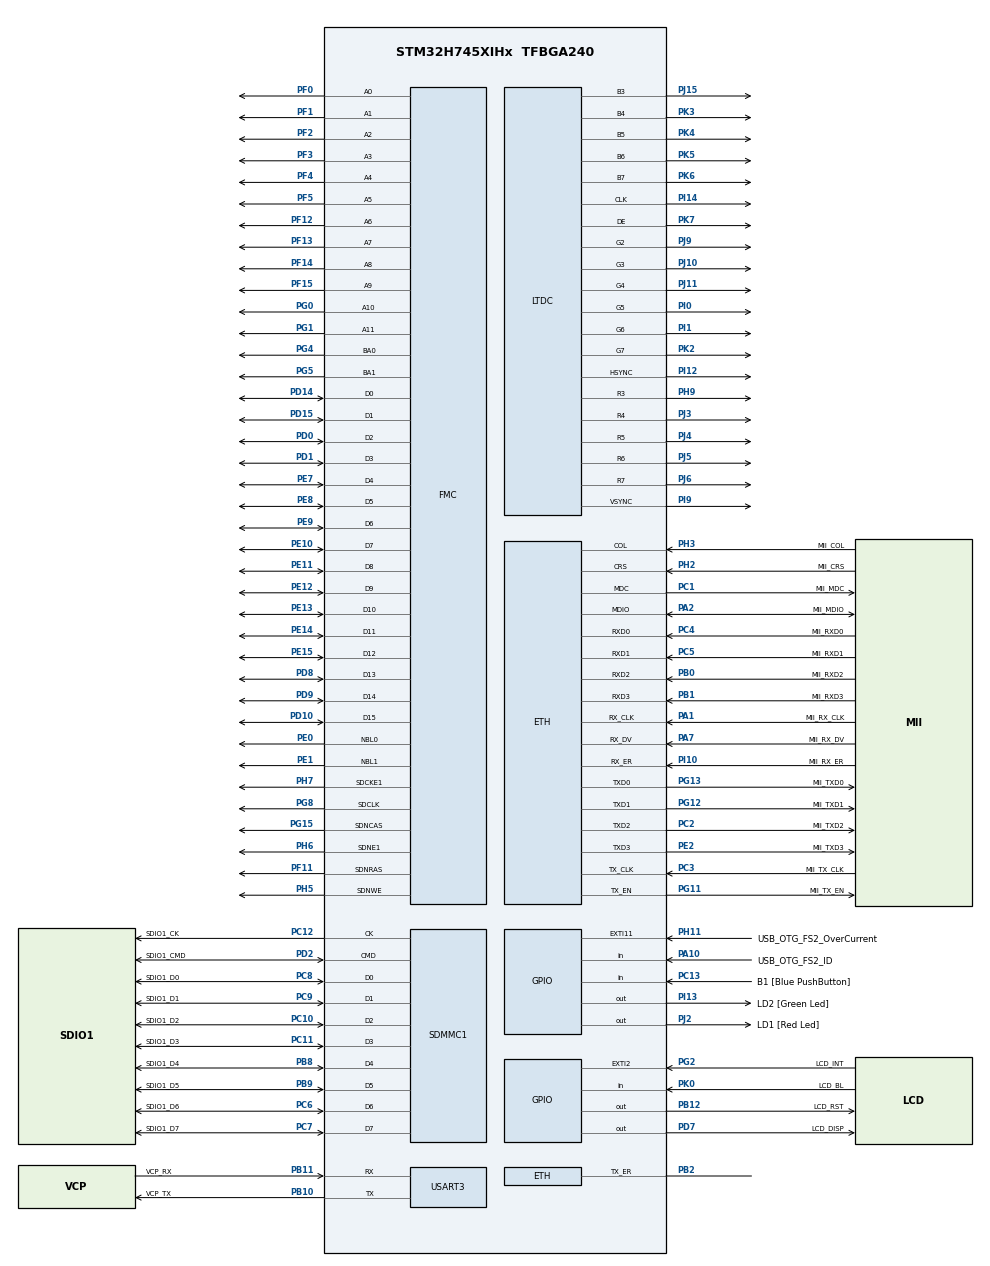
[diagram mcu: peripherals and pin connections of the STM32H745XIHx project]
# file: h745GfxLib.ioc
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CortexM4.IPs=FATFS_M4\:I,FREERTOS_M4\:I,IWDG2\:I,RCC,USB_DEVICE_M4\:I,USB_HOST_M4\:I,WWDG2\:I,DMA,BDMA,MDMA,NVIC2\:I,SAI4\:I,DEBUG,PDM2PCM_M4\:I,PWR,RESMGR_UTILITY,SYS_M4\:I,CORTEX_M4\:I,GPIO,OPENAMP_M4\:I,VREFBUF
CortexM4.Pins=PJ2
CortexM7.IPs=FATFS_M7\:I,FREERTOS_M7\:I,IWDG1\:I,RCC\:I,USB_DEVICE_M7\:I,USB_HOST_M7\:I,WWDG1\:I,DMA\:I,BDMA\:I,MDMA\:I,NVIC1\:I,CORTEX_M7\:I,DEBUG\:I,PDM2PCM_M7\:I,PWR\:I,RESMGR_UTILITY\:I,SYS\:I,GPIO\:I,OPENAMP_M7\:I,VREFBUF\:I,MEMORYMAP\:I,LTDC\:I,USART3\:I,FMC\:I,RNG\:I,SDMMC1\:I,ETH\:I,LWIP\:I,TIM2\:I
CortexM7.Pins=PD7,PA10,PC13,PI13,PG2,PK0,PH11,PB12
ETH.MediaInterface=HAL_ETH_MII_MODE
FATFS_M7._VOLUMES=2
FMC.CASLatency2=FMC_SDRAM_CAS_LATENCY_3
FMC.ExitSelfRefreshDelay2=6
FMC.LoadToActiveDelay2=2
FMC.RCDDelay2=2
FMC.RPDelay1=2
FMC.RPDelay2=2
FMC.ReadBurst1=FMC_SDRAM_RBURST_ENABLE
FMC.ReadBurst2=FMC_SDRAM_RBURST_ENABLE
FMC.ReadPipeDelay2=FMC_SDRAM_RPIPE_DELAY_0
FMC.RowCycleDelay1=6
FMC.RowCycleDelay2=6
FMC.SDClockPeriod1=FMC_SDRAM_CLOCK_PERIOD_2
FMC.SDClockPeriod2=FMC_SDRAM_CLOCK_PERIOD_2
FMC.SelfRefreshTime2=4
FMC.WriteRecoveryTime2=2
FREERTOS_M7.Tasks01=defaultTask,24,8192,StartDefaultTask,Default,NULL,Dynamic,NULL,NULL
FREERTOS_M7.configMINIMAL_STACK_SIZE=8192
FREERTOS_M7.configTOTAL_HEAP_SIZE=131072
FREERTOS_M7.configUSE_NEWLIB_REENTRANT=1
LTDC.ActiveH=272
LTDC.ActiveW=480
LTDC.Alpha0_L0=255
LTDC.Alpha_L0=255
LTDC.DEPolarity=LTDC_DEPOLARITY_AL
LTDC.FBStartAdress_L0=0xd0000000
LTDC.HBP=13
LTDC.HFP=32
LTDC.HSync=41
LTDC.ImageHeight_L0=272
LTDC.ImageWidth_L0=480
LTDC.Layers=0
LTDC.PCPolarity=LTDC_PCPOLARITY_IPC
LTDC.PixelFormat_L0=LTDC_PIXEL_FORMAT_RGB565
LTDC.VSync=10
LTDC.WindowX1_L0=480
LTDC.WindowY1_L0=272
LWIP.BSP.number=1
LWIP.GATEWAY_ADDRESS=192.168.005.001
LWIP.IP_ADDRESS=192.168.005.010
LWIP.LWIP_DHCP=0
LWIP.LWIP_RAM_HEAP_POINTER=0x30020000
LWIP.MEM_SIZE=131048
LWIP.NETMASK_ADDRESS=255.255.255.000
LWIP.Version=v2.1.2_Cube
LWIP0.BSP.STBoard=false
LWIP0.BSP.api=BSP_COMPONENT_DRIVER
LWIP0.BSP.component=LAN8742
LWIP0.BSP.instance=LAN8742
LWIP0.BSP.name=Driver_PHY
LWIP0.BSP.semaphore=S_LAN8742
LWIP0.BSP.solution=LAN8742
Mcu.Family=STM32H7
Mcu.Name=STM32H745XIHx
Mcu.Package=TFBGA240
NVIC1.ETH_IRQn=true\:5\:0\:false\:false\:true\:true\:true\:true\:true
NVIC1.PriorityGroup=NVIC_PRIORITYGROUP_4
NVIC1.TIM2_IRQn=true\:15\:0\:false\:false\:true\:false\:false\:true\:true
NVIC1.TimeBase=TIM2_IRQn
NVIC1.TimeBaseIP=TIM2
NVIC2.PriorityGroup=NVIC_PRIORITYGROUP_4
PA1.GPIO_Label=MII_RX_CLK
PA1.Mode=MII
PA1.PinAttribute=CortexM7
PA1.Signal=ETH_RX_CLK
PA10.GPIO_Label=USB_OTG_FS2_ID
PA10.PinAttribute=CortexM7
PA10.Signal=GPIO_Input
PA11.GPIO_Label=USB_OTG_FS2_N
PA11.Signal=USB_OTG_FS_DM
PA12.GPIO_Label=USB_OTG_FS2_P
PA12.Signal=USB_OTG_FS_DP
PA2.GPIO_Label=MII_MDIO
PA2.Mode=MII
PA2.PinAttribute=CortexM7
PA2.Signal=ETH_MDIO
PA7.GPIO_Label=MII_RX_DV
PA7.Mode=MII
PA7.PinAttribute=CortexM7
PA7.Signal=ETH_RX_DV
PA9.GPIO_Label=VBUS_FS2
PA9.Signal=USB_OTG_FS_VBUS
PB0.GPIO_Label=MII_RXD2
PB0.Mode=MII
PB0.PinAttribute=CortexM7
PB0.Signal=ETH_RXD2
PB1.GPIO_Label=MII_RXD3
PB1.Mode=MII
PB1.PinAttribute=CortexM7
PB1.Signal=ETH_RXD3
PB10.GPIO_Label=VCP_TX
PB10.Mode=Asynchronous
PB10.PinAttribute=CortexM7
PB10.Signal=USART3_TX
PB11.GPIO_Label=VCP_RX
PB11.Mode=Asynchronous
PB11.PinAttribute=CortexM7
PB11.Signal=USART3_RX
PB12.GPIO_Label=LCD_RST
PB12.PinAttribute=CortexM7
PB12.Signal=GPIO_Output
PB13.GPIO_Label=FDCAN2_TX
PB13.Signal=FDCAN2_TX
PB2.Mode=Activate Tx Err signal
PB2.PinAttribute=CortexM7
PB2.Signal=ETH_TX_ER
PB5.GPIO_Label=FDCAN2_RX
PB5.Signal=FDCAN2_RX
PB6.Signal=QUADSPI_BK1_NCS
PB8.GPIO_Label=SDIO1_D4
PB8.Mode=mmc_8_bits_Wide_bus
PB8.PinAttribute=CortexM7
PB8.Signal=SDMMC1_D4
PB9.GPIO_Label=SDIO1_D5
PB9.Mode=mmc_8_bits_Wide_bus
PB9.PinAttribute=CortexM7
PB9.Signal=SDMMC1_D5
PC1.GPIO_Label=MII_MDC
PC1.Mode=MII
PC1.PinAttribute=CortexM7
PC1.Signal=ETH_MDC
PC10.GPIO_Label=SDIO1_D2
PC10.Mode=mmc_8_bits_Wide_bus
PC10.PinAttribute=CortexM7
PC10.Signal=SDMMC1_D2
PC11.GPIO_Label=SDIO1_D3
PC11.Mode=mmc_8_bits_Wide_bus
PC11.PinAttribute=CortexM7
PC11.Signal=SDMMC1_D3
PC12.GPIO_Label=SDIO1_CK
PC12.Mode=mmc_8_bits_Wide_bus
PC12.PinAttribute=CortexM7
PC12.Signal=SDMMC1_CK
PC13.GPIO_Label=B1 [Blue PushButton]
PC13.PinAttribute=CortexM7
PC13.Signal=GPIO_Input
PC14-OSC32_IN\ (OSC32_IN).GPIO_Label=OSC32_IN
PC14-OSC32_IN\ (OSC32_IN).PinAttribute=Free
PC14-OSC32_IN\ (OSC32_IN).Signal=RCC_OSC32_IN
PC15-OSC32_OUT\ (OSC32_OUT).GPIO_Label=OSC32_OUT
PC15-OSC32_OUT\ (OSC32_OUT).PinAttribute=Free
PC15-OSC32_OUT\ (OSC32_OUT).Signal=RCC_OSC32_OUT
PC2.GPIO_Label=MII_TXD2
PC2.Mode=MII
PC2.PinAttribute=CortexM7
PC2.Signal=ETH_TXD2
PC3.GPIO_Label=MII_TX_CLK
PC3.Mode=MII
PC3.PinAttribute=CortexM7
PC3.Signal=ETH_TX_CLK
PC4.GPIO_Label=MII_RXD0
PC4.Mode=MII
PC4.PinAttribute=CortexM7
PC4.Signal=ETH_RXD0
PC5.GPIO_Label=MII_RXD1
PC5.Mode=MII
PC5.PinAttribute=CortexM7
PC5.Signal=ETH_RXD1
PC6.GPIO_Label=SDIO1_D6
PC6.Mode=mmc_8_bits_Wide_bus
PC6.PinAttribute=CortexM7
PC6.Signal=SDMMC1_D6
PC7.GPIO_Label=SDIO1_D7
PC7.Mode=mmc_8_bits_Wide_bus
PC7.PinAttribute=CortexM7
PC7.Signal=SDMMC1_D7
PC8.GPIO_Label=SDIO1_D0
PC8.Mode=mmc_8_bits_Wide_bus
PC8.PinAttribute=CortexM7
PC8.Signal=SDMMC1_D0
PC9.GPIO_Label=SDIO1_D1
PC9.Mode=mmc_8_bits_Wide_bus
PC9.PinAttribute=CortexM7
PC9.Signal=SDMMC1_D1
PD0.PinAttribute=CortexM7
PD0.Signal=FMC_D2_DA2
PD1.PinAttribute=CortexM7
PD1.Signal=FMC_D3_DA3
PD10.PinAttribute=CortexM7
PD10.Signal=FMC_D15_DA15
PD11.Signal=QUADSPI_BK1_IO0
PD14.PinAttribute=CortexM7
PD14.Signal=FMC_D0_DA0
PD15.PinAttribute=CortexM7
PD15.Signal=FMC_D1_DA1
PD2.GPIO_Label=SDIO1_CMD
PD2.Mode=mmc_8_bits_Wide_bus
PD2.PinAttribute=CortexM7
PD2.Signal=SDMMC1_CMD
PD7.GPIO_Label=LCD_DISP
PD7.PinAttribute=CortexM7
PD7.Signal=GPIO_Output
PD8.PinAttribute=CortexM7
PD8.Signal=FMC_D13_DA13
PD9.PinAttribute=CortexM7
PD9.Signal=FMC_D14_DA14
PE0.PinAttribute=CortexM7
PE0.Signal=FMC_NBL0
PE1.PinAttribute=CortexM7
PE1.Signal=FMC_NBL1
PE10.PinAttribute=CortexM7
PE10.Signal=FMC_D7_DA7
PE11.PinAttribute=CortexM7
PE11.Signal=FMC_D8_DA8
PE12.PinAttribute=CortexM7
PE12.Signal=FMC_D9_DA9
PE13.PinAttribute=CortexM7
PE13.Signal=FMC_D10_DA10
PE14.PinAttribute=CortexM7
PE14.Signal=FMC_D11_DA11
PE15.PinAttribute=CortexM7
PE15.Signal=FMC_D12_DA12
PE2.GPIO_Label=MII_TXD3
PE2.Mode=MII
PE2.PinAttribute=CortexM7
PE2.Signal=ETH_TXD3
PE4.PinAttribute=CortexM4
PE4.Signal=SAI4_D2
PE5.PinAttribute=CortexM4
PE5.Signal=SAI4_CK2
PE7.PinAttribute=CortexM7
PE7.Signal=FMC_D4_DA4
PE8.PinAttribute=CortexM7
PE8.Signal=FMC_D5_DA5
PE9.PinAttribute=CortexM7
PE9.Signal=FMC_D6_DA6
PF0.PinAttribute=CortexM7
PF0.Signal=FMC_A0
PF1.PinAttribute=CortexM7
PF1.Signal=FMC_A1
PF10.Signal=QUADSPI_CLK
PF11.PinAttribute=CortexM7
PF11.Signal=FMC_SDNRAS
PF12.PinAttribute=CortexM7
PF12.Signal=FMC_A6
PF13.PinAttribute=CortexM7
PF13.Signal=FMC_A7
PF14.PinAttribute=CortexM7
PF14.Signal=FMC_A8
PF15.PinAttribute=CortexM7
PF15.Signal=FMC_A9
PF2.PinAttribute=CortexM7
PF2.Signal=FMC_A2
PF3.PinAttribute=CortexM7
PF3.Signal=FMC_A3
PF4.PinAttribute=CortexM7
PF4.Signal=FMC_A4
PF5.PinAttribute=CortexM7
PF5.Signal=FMC_A5
PF6.Signal=QUADSPI_BK1_IO3
PF7.Signal=QUADSPI_BK1_IO2
PF9.Signal=QUADSPI_BK1_IO1
PG0.PinAttribute=CortexM7
PG0.Signal=FMC_A10
PG1.PinAttribute=CortexM7
PG1.Signal=FMC_A11
PG10.Signal=SAI2_SD_B
PG11.GPIO_Label=MII_TX_EN
PG11.Mode=MII
PG11.PinAttribute=CortexM7
PG11.Signal=ETH_TX_EN
PG12.GPIO_Label=MII_TXD1
PG12.Mode=MII
PG12.PinAttribute=CortexM7
PG12.Signal=ETH_TXD1
PG13.GPIO_Label=MII_TXD0
PG13.Mode=MII
PG13.PinAttribute=CortexM7
PG13.Signal=ETH_TXD0
PG15.PinAttribute=CortexM7
PG15.Signal=FMC_SDNCAS
PG2.GPIO_Label=LCD_INT
PG2.PinAttribute=CortexM7
PG2.Signal=GPXTI2
PG4.PinAttribute=CortexM7
PG4.Signal=FMC_A14_BA0
PG5.PinAttribute=CortexM7
PG5.Signal=FMC_A15_BA1
PG8.PinAttribute=CortexM7
PG8.Signal=FMC_SDCLK
PH0-OSC_IN\ (PH0).GPIO_Label=OSC_IN
PH0-OSC_IN\ (PH0).Mode=HSE-External-Clock-Source
PH0-OSC_IN\ (PH0).PinAttribute=Free
PH0-OSC_IN\ (PH0).Signal=RCC_OSC_IN
PH1-OSC_OUT\ (PH1).GPIO_Label=OSC_OUT
PH1-OSC_OUT\ (PH1).PinAttribute=Free
PH1-OSC_OUT\ (PH1).Signal=RCC_OSC_OUT
PH11.GPIO_Label=USB_OTG_FS2_OverCurrent
PH11.PinAttribute=CortexM7
PH11.Signal=GPXTI11
PH13.GPIO_Label=FDCAN1_TX
PH13.Signal=FDCAN1_TX
PH14.GPIO_Label=FDCAN2_RX
PH14.Signal=FDCAN1_RX
PH2.GPIO_Label=MII_CRS
PH2.Mode=MII
PH2.PinAttribute=CortexM7
PH2.Signal=ETH_CRS
PH3.GPIO_Label=MII_COL
PH3.Mode=MII
PH3.PinAttribute=CortexM7
PH3.Signal=ETH_COL
PH5.PinAttribute=CortexM7
PH5.Signal=FMC_SDNWE
PH6.Mode=SdramChipSelect2_2
PH6.PinAttribute=CortexM7
PH6.Signal=FMC_SDNE1
PH7.Mode=SdramChipSelect2_2
PH7.PinAttribute=CortexM7
PH7.Signal=FMC_SDCKE1
PH9.Mode=RGB565
PH9.PinAttribute=CortexM7
PH9.Signal=LTDC_R3
PI0.Mode=RGB565
PI0.PinAttribute=CortexM7
PI0.Signal=LTDC_G5
PI1.Mode=RGB565
PI1.PinAttribute=CortexM7
PI1.Signal=LTDC_G6
PI10.GPIO_Label=MII_RX_ER
PI10.Mode=Activate Rx Err signal
PI10.PinAttribute=CortexM7
PI10.Signal=ETH_RX_ER
PI12.Mode=RGB565
PI12.PinAttribute=CortexM7
PI12.Signal=LTDC_HSYNC
PI13.GPIO_Label=LD2 [Green Led]
PI13.PinAttribute=CortexM7
PI13.Signal=GPIO_Output
PI14.Mode=RGB565
PI14.PinAttribute=CortexM7
PI14.Signal=LTDC_CLK
PI15.PinAttribute=CortexM7
PI15.Signal=LTDC_R0
PI4.Signal=SAI2_MCLK_A
PI5.Signal=SAI2_SCK_A
PI6.Signal=SAI2_SD_A
PI7.Signal=SAI2_FS_A
PI9.Mode=RGB565
PI9.PinAttribute=CortexM7
PI9.Signal=LTDC_VSYNC
PJ0.PinAttribute=CortexM7
PJ0.Signal=LTDC_R1
PJ1.PinAttribute=CortexM7
PJ1.Signal=LTDC_R2
PJ10.Mode=RGB565
PJ10.PinAttribute=CortexM7
PJ10.Signal=LTDC_G3
PJ11.Mode=RGB565
PJ11.PinAttribute=CortexM7
PJ11.Signal=LTDC_G4
PJ12.PinAttribute=CortexM7
PJ12.Signal=LTDC_B0
PJ13.PinAttribute=CortexM7
PJ13.Signal=LTDC_B1
PJ14.PinAttribute=CortexM7
PJ14.Signal=LTDC_B2
PJ15.Mode=RGB565
PJ15.PinAttribute=CortexM7
PJ15.Signal=LTDC_B3
PJ2.GPIO_Label=LD1 [Red Led]
PJ2.PinAttribute=CortexM4
PJ2.Signal=GPIO_Output
PJ3.Mode=RGB565
PJ3.PinAttribute=CortexM7
PJ3.Signal=LTDC_R4
PJ4.Mode=RGB565
PJ4.PinAttribute=CortexM7
PJ4.Signal=LTDC_R5
PJ5.Mode=RGB565
PJ5.PinAttribute=CortexM7
PJ5.Signal=LTDC_R6
PJ6.Mode=RGB565
PJ6.PinAttribute=CortexM7
PJ6.Signal=LTDC_R7
PJ7.PinAttribute=CortexM7
PJ7.Signal=LTDC_G0
PJ8.PinAttribute=CortexM7
PJ8.Signal=LTDC_G1
PJ9.Mode=RGB565
PJ9.PinAttribute=CortexM7
PJ9.Signal=LTDC_G2
PK0.GPIO_Label=LCD_BL
PK0.PinAttribute=CortexM7
PK0.Signal=GPIO_Input
PK2.Mode=RGB565
PK2.PinAttribute=CortexM7
PK2.Signal=LTDC_G7
PK3.Mode=RGB565
PK3.PinAttribute=CortexM7
PK3.Signal=LTDC_B4
PK4.Mode=RGB565
PK4.PinAttribute=CortexM7
PK4.Signal=LTDC_B5
PK5.Mode=RGB565
PK5.PinAttribute=CortexM7
PK5.Signal=LTDC_B6
PK6.Mode=RGB565
PK6.PinAttribute=CortexM7
PK6.Signal=LTDC_B7
PK7.Mode=RGB565
PK7.PinAttribute=CortexM7
PK7.Signal=LTDC_DE
ProjectManager.HeapSize=M4-0x200,M7-0x200
ProjectManager.StackSize=M4-0x400,M7-0x400
ProjectManager.TargetToolchain=STM32CubeIDE
RCC.ADCFreq_Value=400000000
RCC.APB1Freq_Value=100000000
RCC.APB2Freq_Value=100000000
RCC.APB3Freq_Value=100000000
RCC.APB4Freq_Value=100000000
RCC.CortexFreq_Value=400000000
RCC.D1PPRE=RCC_APB3_DIV2
RCC.D2PPRE1=RCC_APB1_DIV2
RCC.D2PPRE2=RCC_APB2_DIV2
RCC.D3PPRE=RCC_APB4_DIV2
RCC.DIVM1=5
RCC.DIVM2=5
RCC.DIVM3=5
RCC.DIVN1=160
RCC.DIVN2=160
RCC.DIVN3=160
RCC.DIVQ1=4
RCC.DIVR1=4
RCC.DIVR2=8
RCC.DIVR3=83
RCC.FMCCLockSelection=RCC_FMCCLKSOURCE_PLL
RCC.HCLKFreq_Value=200000000
RCC.HPRE=RCC_HCLK_DIV2
RCC.PLL2FRACN=0
RCC.PLL3FRACN=0
RCC.PLLFRACN=0
RCC.PLLSourceVirtual=RCC_PLLSOURCE_HSE
RCC.SDMMC1CLockSelection=RCC_SDMMCCLKSOURCE_PLL2
RCC.SYSCLKFreq_VALUE=400000000
RCC.SYSCLKSource=RCC_SYSCLKSOURCE_PLLCLK
RCC.SupplySource=PWR_DIRECT_SMPS_SUPPLY
RCC.USBFreq_Value=200000000
SDMMC1.ClockDiv=25
SH.FMC_A0.0=FMC_A0,12b-sda2
SH.FMC_A1.0=FMC_A1,12b-sda2
SH.FMC_A10.0=FMC_A10,12b-sda2
SH.FMC_A11.0=FMC_A11,12b-sda2
SH.FMC_A14_BA0.0=FMC_BA0,FourSdramBanks2
SH.FMC_A15_BA1.0=FMC_BA1,FourSdramBanks2
SH.FMC_A2.0=FMC_A2,12b-sda2
SH.FMC_A3.0=FMC_A3,12b-sda2
SH.FMC_A4.0=FMC_A4,12b-sda2
SH.FMC_A5.0=FMC_A5,12b-sda2
SH.FMC_A6.0=FMC_A6,12b-sda2
SH.FMC_A7.0=FMC_A7,12b-sda2
SH.FMC_A8.0=FMC_A8,12b-sda2
SH.FMC_A9.0=FMC_A9,12b-sda2
SH.FMC_D0_DA0.0=FMC_D0,sd-16b-d2
SH.FMC_D10_DA10.0=FMC_D10,sd-16b-d2
SH.FMC_D11_DA11.0=FMC_D11,sd-16b-d2
SH.FMC_D12_DA12.0=FMC_D12,sd-16b-d2
SH.FMC_D13_DA13.0=FMC_D13,sd-16b-d2
SH.FMC_D14_DA14.0=FMC_D14,sd-16b-d2
SH.FMC_D15_DA15.0=FMC_D15,sd-16b-d2
SH.FMC_D1_DA1.0=FMC_D1,sd-16b-d2
SH.FMC_D2_DA2.0=FMC_D2,sd-16b-d2
SH.FMC_D3_DA3.0=FMC_D3,sd-16b-d2
SH.FMC_D4_DA4.0=FMC_D4,sd-16b-d2
SH.FMC_D5_DA5.0=FMC_D5,sd-16b-d2
SH.FMC_D6_DA6.0=FMC_D6,sd-16b-d2
SH.FMC_D7_DA7.0=FMC_D7,sd-16b-d2
SH.FMC_D8_DA8.0=FMC_D8,sd-16b-d2
SH.FMC_D9_DA9.0=FMC_D9,sd-16b-d2
SH.FMC_NBL0.0=FMC_NBL0,Sd2ByteEnable2
SH.FMC_NBL1.0=FMC_NBL1,Sd2ByteEnable2
SH.FMC_SDCLK.0=FMC_SDCLK,12b-sda2
SH.FMC_SDNCAS.0=FMC_SDNCAS,12b-sda2
SH.FMC_SDNRAS.0=FMC_SDNRAS,12b-sda2
SH.FMC_SDNWE.0=FMC_SDNWE,12b-sda2
USART3.VirtualMode-Asynchronous=VM_ASYNC
VP_FATFS_M7_VS_Generic.Mode=User_defined
VP_FREERTOS_M7_VS_CMSIS_V2.Mode=CMSIS_V2
VP_LWIP_VS_Enabled.Mode=Enabled
VP_MEMORYMAP_VS_MEMORYMAP.Mode=CurAppReg
VP_RNG_VS_RNG.Mode=RNG_Activate
VP_SYS_M4_VS_Systick.Mode=SysTick
VP_SYS_VS_tim2.Mode=TIM2
board=STM32H745I-DISCO

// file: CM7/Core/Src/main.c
/* USER CODE BEGIN Header */
/**
  ******************************************************************************
  * @file           : main.c
  * @brief          : Main program body
  ******************************************************************************
  * @attention
  *
  * Copyright (c) 2025 STMicroelectronics.
  * All rights reserved.
  *
  * This software is licensed under terms that can be found in the LICENSE file
  * in the root directory of this software component.
  * If no LICENSE file comes with this software, it is provided AS-IS.
  *
  ******************************************************************************
  */
/* USER CODE END Header */
#include "main.h"
#include "cmsis_os.h"
#include "fatfs.h"
#include "lwip.h"

/* USER CODE BEGIN Includes */

//peripherals are assigned to the specific core in .ioc view

//sdram needs chip-specific initialization ( apart from controller init )
//https://community.st.com/t5/stm32-mcus-products/hardfault-when-trying-to-access-sdram-on-stm32h745i-disco/td-p/707581

//check the display on pin ( PD7 ) was input by default ( 4hrs lost )

//eth/lwip guide
//Enable ethernet global interrupt
//https://community.st.com/t5/stm32-mcus/how-to-create-a-project-for-stm32h7-with-ethernet-and-lwip-stack/ta-p/49308

//https://www.nongnu.org/lwip/2_1_x/group__lwip__nosys.html

//https://controllerstech.com/stm32-ethernet-4-tcp-server/
//https://github.com/stm32-hotspot/STM32H7-LwIP-Examples/tree/main
//https://controllerstech.com/stm32-ethernet-4-tcp-server/
//cache issue
//https://community.st.com/t5/stm32cubemx-mcus/lwip-v6-5-0-stmh32h735-disco-https-github-com-stm32-hotspot/td-p/91721

//CHECK
//lwip/target/ethernetif.c
//line802
//void HAL_ETH_RxLinkCallback(void **pStart, void **pEnd, uint8_t *buff, uint16_t Length)
//data cache invalidation causes hardfault (datacache off in this project)

//FREERTOS
//Adjust heap and minimal stack size, default is way to small

#include "mt48lc4m32b2.h"
#include "rk043fn48h.h"
#include "emmcDrv.h"
#include <stdio.h>
#include <stdlib.h>

#include "bsp.h"
#include "gfFont.h"
#include "gfBitmap.h"
#include "gfDrawing.h"
#include "osAlloc.h"

/* USER CODE END Includes */

/* USER CODE BEGIN PD */

#ifndef HSEM_ID_0
#define HSEM_ID_0 (0U) /* HW semaphore 0*/
#endif

/* USER CODE END PD */

LTDC_HandleTypeDef hltdc;

RNG_HandleTypeDef hrng;

MMC_HandleTypeDef hmmc1;

UART_HandleTypeDef huart3;

SDRAM_HandleTypeDef hsdram2;

/* Definitions for defaultTask */
osThreadId_t defaultTaskHandle;
const osThreadAttr_t defaultTask_attributes = {
  .name = "defaultTask",
  .stack_size = 8192 * 4,
  .priority = (osPriority_t) osPriorityNormal,
};

void SystemClock_Config(void);
static void MX_GPIO_Init(void);
static void MX_LTDC_Init(void);
static void MX_USART3_UART_Init(void);
static void MX_FMC_Init(void);
static void MX_SDMMC1_MMC_Init(void);
static void MX_RNG_Init(void);
void StartDefaultTask(void *argument);

/* USER CODE BEGIN 0 */

extern const Diskio_drvTypeDef  emmcDriverStruct;

char        emmcPath[4];
uint8_t     workBuffer[_MAX_SS];

FATFS       fatFs;
FIL         fil;

uint32_t                conReady = 0;
extern tgfTextOverlay   con;
tgfBitmap               screen;

//override putchar -> printf redirected to uart

int __io_putchar( int ch )
{
   char buf[2];

   HAL_UART_Transmit( &huart3, (uint8_t *)&ch, 1, 0xFFFF );

   if( conReady )
   {

      if( ch != '\r' )
      {
         buf[0] = (uint8_t)ch;
         buf[1] = 0;

         toPrint( &con, buf );
      }
   }
   return ch;
}

/* USER CODE END 0 */

int main(void)
{

  /* USER CODE BEGIN 1 */
  FRESULT   res;
  /* USER CODE END 1 */
/* USER CODE BEGIN Boot_Mode_Sequence_0 */
   int32_t  timeout;
/* USER CODE END Boot_Mode_Sequence_0 */

/* USER CODE BEGIN Boot_Mode_Sequence_1 */
  /* Wait until CPU2 boots and enters in stop mode or timeout*/
  timeout = 0xFFFF;
  while((__HAL_RCC_GET_FLAG(RCC_FLAG_D2CKRDY) != RESET) && (timeout-- > 0));
  if ( timeout < 0 )
  {
  Error_Handler();
  }
/* USER CODE END Boot_Mode_Sequence_1 */
  /* MCU Configuration--------------------------------------------------------*/

  /* Reset of all peripherals, Initializes the Flash interface and the Systick. */
  HAL_Init();

  /* Configure the system clock */
  SystemClock_Config();
/* USER CODE BEGIN Boot_Mode_Sequence_2 */

  /* When system initialization is finished, Cortex-M7 will release Cortex-M4 by means of
   HSEM notification */

  /*HW semaphore Clock enable*/
  __HAL_RCC_HSEM_CLK_ENABLE();

  /*Take HSEM */
  HAL_HSEM_FastTake(HSEM_ID_0);

  /*Release HSEM in order to notify the CPU2(CM4)*/
  HAL_HSEM_Release(HSEM_ID_0,0);

  /* wait until CPU2 wakes up from stop mode */
  timeout = 0xFFFF;

  while((__HAL_RCC_GET_FLAG(RCC_FLAG_D2CKRDY) == RESET) && (timeout-- > 0));
  if ( timeout < 0 )
  {
     Error_Handler();
  }

/* USER CODE END Boot_Mode_Sequence_2 */

  /* Initialize all configured peripherals */
  MX_GPIO_Init();
  MX_LTDC_Init();
  MX_USART3_UART_Init();
  MX_FMC_Init();
  MX_SDMMC1_MMC_Init();
  MX_FATFS_Init();
  MX_RNG_Init();
  /* USER CODE BEGIN 2 */

  //init emmc driver
  emmcDrvInit( &hmmc1 );

  //unlink user driver
  FATFS_UnLinkDriver( "0:" );

  //link emmc driver
  FATFS_LinkDriver( &emmcDriverStruct, emmcPath );

  printf( "emmcPath: '%s'\r\n", emmcPath );

  res = f_mount( &fatFs, (TCHAR const*)emmcPath, 0 );

/*  res = f_open( &fil, "0:test.txt", FA_READ );

  bw = 0;

  res = f_read( &fil, workBuffer , 11, &bw );
  workBuffer[bw] = 0;

  f_close( &fil );

  printf( "|%s|\r\n", workBuffer );

  conRedraw( &con );
*/

  /*res = f_mkfs(emmcPath, FS_FAT32, 0, workBuffer, sizeof(workBuffer));

  if (res != FR_OK)
  {
    printf( "ERROR: f_mkfs failed\r\n");
  }
*/

  /* USER CODE END 2 */

  /* Init scheduler */
  osKernelInitialize();

  /* Create the thread(s) */
  /* creation of defaultTask */
  defaultTaskHandle = osThreadNew(StartDefaultTask, NULL, &defaultTask_attributes);

  /* Start scheduler */
  osKernelStart();

  /* We should never get here as control is now taken by the scheduler */

  /* Infinite loop */
  while (1)
  {

  }
}

void SystemClock_Config(void)
{
  RCC_OscInitTypeDef RCC_OscInitStruct = {0};
  RCC_ClkInitTypeDef RCC_ClkInitStruct = {0};

  /** Supply configuration update enable
  */
  HAL_PWREx_ConfigSupply(PWR_DIRECT_SMPS_SUPPLY);

  /** Configure the main internal regulator output voltage
  */
  __HAL_PWR_VOLTAGESCALING_CONFIG(PWR_REGULATOR_VOLTAGE_SCALE1);

  while(!__HAL_PWR_GET_FLAG(PWR_FLAG_VOSRDY)) {}

  /** Initializes the RCC Oscillators according to the specified parameters
  * in the RCC_OscInitTypeDef structure.
  */
  RCC_OscInitStruct.OscillatorType = RCC_OSCILLATORTYPE_HSI48|RCC_OSCILLATORTYPE_HSE;
  RCC_OscInitStruct.HSEState = RCC_HSE_BYPASS;
  RCC_OscInitStruct.HSI48State = RCC_HSI48_ON;
  RCC_OscInitStruct.PLL.PLLState = RCC_PLL_ON;
  RCC_OscInitStruct.PLL.PLLSource = RCC_PLLSOURCE_HSE;
  RCC_OscInitStruct.PLL.PLLM = 5;
  RCC_OscInitStruct.PLL.PLLN = 160;
  RCC_OscInitStruct.PLL.PLLP = 2;
  RCC_OscInitStruct.PLL.PLLQ = 4;
  RCC_OscInitStruct.PLL.PLLR = 4;
  RCC_OscInitStruct.PLL.PLLRGE = RCC_PLL1VCIRANGE_2;
  RCC_OscInitStruct.PLL.PLLVCOSEL = RCC_PLL1VCOWIDE;
  RCC_OscInitStruct.PLL.PLLFRACN = 0;
  if (HAL_RCC_OscConfig(&RCC_OscInitStruct) != HAL_OK)
  {
    Error_Handler();
  }

  /** Initializes the CPU, AHB and APB buses clocks
  */
  RCC_ClkInitStruct.ClockType = RCC_CLOCKTYPE_HCLK|RCC_CLOCKTYPE_SYSCLK
                              |RCC_CLOCKTYPE_PCLK1|RCC_CLOCKTYPE_PCLK2
                              |RCC_CLOCKTYPE_D3PCLK1|RCC_CLOCKTYPE_D1PCLK1;
  RCC_ClkInitStruct.SYSCLKSource = RCC_SYSCLKSOURCE_PLLCLK;
  RCC_ClkInitStruct.SYSCLKDivider = RCC_SYSCLK_DIV1;
  RCC_ClkInitStruct.AHBCLKDivider = RCC_HCLK_DIV2;
  RCC_ClkInitStruct.APB3CLKDivider = RCC_APB3_DIV2;
  RCC_ClkInitStruct.APB1CLKDivider = RCC_APB1_DIV2;
  RCC_ClkInitStruct.APB2CLKDivider = RCC_APB2_DIV2;
  RCC_ClkInitStruct.APB4CLKDivider = RCC_APB4_DIV2;

  if (HAL_RCC_ClockConfig(&RCC_ClkInitStruct, FLASH_LATENCY_2) != HAL_OK)
  {
    Error_Handler();
  }
}

static void MX_LTDC_Init(void)
{

  LTDC_LayerCfgTypeDef pLayerCfg = {0};

  /* USER CODE BEGIN LTDC_Init 1 */

  hltdc.Instance = LTDC;
  HAL_LTDC_DeInit(&hltdc);

  /* USER CODE END LTDC_Init 1 */
  hltdc.Instance = LTDC;
  hltdc.Init.HSPolarity = LTDC_HSPOLARITY_AL;
  hltdc.Init.VSPolarity = LTDC_VSPOLARITY_AL;
  hltdc.Init.DEPolarity = LTDC_DEPOLARITY_AL;
  hltdc.Init.PCPolarity = LTDC_PCPOLARITY_IPC;
  hltdc.Init.HorizontalSync = 40;
  hltdc.Init.VerticalSync = 9;
  hltdc.Init.AccumulatedHBP = 53;
  hltdc.Init.AccumulatedVBP = 11;
  hltdc.Init.AccumulatedActiveW = 533;
  hltdc.Init.AccumulatedActiveH = 283;
  hltdc.Init.TotalWidth = 565;
  hltdc.Init.TotalHeigh = 285;
  hltdc.Init.Backcolor.Blue = 0;
  hltdc.Init.Backcolor.Green = 0;
  hltdc.Init.Backcolor.Red = 0;
  if (HAL_LTDC_Init(&hltdc) != HAL_OK)
  {
    Error_Handler();
  }
  pLayerCfg.WindowX0 = 0;
  pLayerCfg.WindowX1 = 480;
  pLayerCfg.WindowY0 = 0;
  pLayerCfg.WindowY1 = 272;
  pLayerCfg.PixelFormat = LTDC_PIXEL_FORMAT_RGB565;
  pLayerCfg.Alpha = 255;
  pLayerCfg.Alpha0 = 255;
  pLayerCfg.BlendingFactor1 = LTDC_BLENDING_FACTOR1_CA;
  pLayerCfg.BlendingFactor2 = LTDC_BLENDING_FACTOR2_CA;
  pLayerCfg.FBStartAdress = 0xd0000000;
  pLayerCfg.ImageWidth = 480;
  pLayerCfg.ImageHeight = 272;
  pLayerCfg.Backcolor.Blue = 0;
  pLayerCfg.Backcolor.Green = 0;
  pLayerCfg.Backcolor.Red = 0;
  if (HAL_LTDC_ConfigLayer(&hltdc, &pLayerCfg, 0) != HAL_OK)
  {
    Error_Handler();
  }
  /* USER CODE BEGIN LTDC_Init 2 */

  // assert PD7 ( LCD_DISP ) in gpio init

  __HAL_LTDC_ENABLE(&hltdc);
  HAL_LTDC_DisableColorKeying(&hltdc, 0);
  __HAL_LTDC_LAYER_ENABLE(&hltdc, 0 );

  /* USER CODE END LTDC_Init 2 */

}

static void MX_RNG_Init(void)
{

  hrng.Instance = RNG;
  hrng.Init.ClockErrorDetection = RNG_CED_ENABLE;
  if (HAL_RNG_Init(&hrng) != HAL_OK)
  {
    Error_Handler();
  }

}

static void MX_SDMMC1_MMC_Init(void)
{

  hmmc1.Instance = SDMMC1;
  hmmc1.Init.ClockEdge = SDMMC_CLOCK_EDGE_RISING;
  hmmc1.Init.ClockPowerSave = SDMMC_CLOCK_POWER_SAVE_DISABLE;
  hmmc1.Init.BusWide = SDMMC_BUS_WIDE_8B;
  hmmc1.Init.HardwareFlowControl = SDMMC_HARDWARE_FLOW_CONTROL_DISABLE;
  hmmc1.Init.ClockDiv = 25;
  if (HAL_MMC_Init(&hmmc1) != HAL_OK)
  {
    Error_Handler();
  }

}

static void MX_USART3_UART_Init(void)
{

  huart3.Instance = USART3;
  huart3.Init.BaudRate = 115200;
  huart3.Init.WordLength = UART_WORDLENGTH_8B;
  huart3.Init.StopBits = UART_STOPBITS_1;
  huart3.Init.Parity = UART_PARITY_NONE;
  huart3.Init.Mode = UART_MODE_TX_RX;
  huart3.Init.HwFlowCtl = UART_HWCONTROL_NONE;
  huart3.Init.OverSampling = UART_OVERSAMPLING_16;
  huart3.Init.OneBitSampling = UART_ONE_BIT_SAMPLE_DISABLE;
  huart3.Init.ClockPrescaler = UART_PRESCALER_DIV1;
  huart3.AdvancedInit.AdvFeatureInit = UART_ADVFEATURE_NO_INIT;
  if (HAL_UART_Init(&huart3) != HAL_OK)
  {
    Error_Handler();
  }
  if (HAL_UARTEx_SetTxFifoThreshold(&huart3, UART_TXFIFO_THRESHOLD_1_8) != HAL_OK)
  {
    Error_Handler();
  }
  if (HAL_UARTEx_SetRxFifoThreshold(&huart3, UART_RXFIFO_THRESHOLD_1_8) != HAL_OK)
  {
    Error_Handler();
  }
  if (HAL_UARTEx_DisableFifoMode(&huart3) != HAL_OK)
  {
    Error_Handler();
  }

}

/* FMC initialization function */
void MX_FMC_Init(void)
{

  /* USER CODE BEGIN FMC_Init 0 */

   MT48LC4M32B2_Context_t ctx;

  /* USER CODE END FMC_Init 0 */

  FMC_SDRAM_TimingTypeDef SdramTiming = {0};

  /** Perform the SDRAM2 memory initialization sequence
  */
  hsdram2.Instance = FMC_SDRAM_DEVICE;
  /* hsdram2.Init */
  hsdram2.Init.SDBank = FMC_SDRAM_BANK2;
  hsdram2.Init.ColumnBitsNumber = FMC_SDRAM_COLUMN_BITS_NUM_8;
  hsdram2.Init.RowBitsNumber = FMC_SDRAM_ROW_BITS_NUM_12;
  hsdram2.Init.MemoryDataWidth = FMC_SDRAM_MEM_BUS_WIDTH_16;
  hsdram2.Init.InternalBankNumber = FMC_SDRAM_INTERN_BANKS_NUM_4;
  hsdram2.Init.CASLatency = FMC_SDRAM_CAS_LATENCY_3;
  hsdram2.Init.WriteProtection = FMC_SDRAM_WRITE_PROTECTION_DISABLE;
  hsdram2.Init.SDClockPeriod = FMC_SDRAM_CLOCK_PERIOD_2;
  hsdram2.Init.ReadBurst = FMC_SDRAM_RBURST_ENABLE;
  hsdram2.Init.ReadPipeDelay = FMC_SDRAM_RPIPE_DELAY_0;
  /* SdramTiming */
  SdramTiming.LoadToActiveDelay = 2;
  SdramTiming.ExitSelfRefreshDelay = 6;
  SdramTiming.SelfRefreshTime = 4;
  SdramTiming.RowCycleDelay = 6;
  SdramTiming.WriteRecoveryTime = 2;
  SdramTiming.RPDelay = 2;
  SdramTiming.RCDDelay = 2;

  if (HAL_SDRAM_Init(&hsdram2, &SdramTiming) != HAL_OK)
  {
    Error_Handler( );
  }

  /* USER CODE BEGIN FMC_Init 2 */

  // initialize sdram chip

  ctx.TargetBank      = FMC_SDRAM_CMD_TARGET_BANK2;
  ctx.RefreshMode     = MT48LC4M32B2_AUTOREFRESH_MODE_CMD;
  ctx.RefreshRate     = REFRESH_COUNT;
  ctx.BurstLength     = MT48LC4M32B2_BURST_LENGTH_1;        //was 1
  ctx.BurstType       = MT48LC4M32B2_BURST_TYPE_SEQUENTIAL;
  ctx.CASLatency      = MT48LC4M32B2_CAS_LATENCY_3;         //was 3
  ctx.OperationMode   = MT48LC4M32B2_OPERATING_MODE_STANDARD;
  ctx.WriteBurstMode  = MT48LC4M32B2_WRITEBURST_MODE_SINGLE;

  MT48LC4M32B2_Init( &hsdram2, &ctx );

  /* USER CODE END FMC_Init 2 */
}

static void MX_GPIO_Init(void)
{
  GPIO_InitTypeDef GPIO_InitStruct = {0};

  /* GPIO Ports Clock Enable */
  __HAL_RCC_GPIOK_CLK_ENABLE();
  __HAL_RCC_GPIOC_CLK_ENABLE();
  __HAL_RCC_GPIOI_CLK_ENABLE();
  __HAL_RCC_GPIOE_CLK_ENABLE();
  __HAL_RCC_GPIOG_CLK_ENABLE();
  __HAL_RCC_GPIOJ_CLK_ENABLE();
  __HAL_RCC_GPIOD_CLK_ENABLE();
  __HAL_RCC_GPIOB_CLK_ENABLE();
  __HAL_RCC_GPIOA_CLK_ENABLE();
  __HAL_RCC_GPIOF_CLK_ENABLE();
  __HAL_RCC_GPIOH_CLK_ENABLE();

  /*Configure GPIO pin Output Level */
  HAL_GPIO_WritePin(LCD_DISP_GPIO_Port, LCD_DISP_Pin, GPIO_PIN_RESET);

  /*Configure GPIO pin Output Level */
  HAL_GPIO_WritePin(LD2_GPIO_Port, LD2_Pin, GPIO_PIN_RESET);

  /*Configure GPIO pin Output Level */
  HAL_GPIO_WritePin(LCD_RST_GPIO_Port, LCD_RST_Pin, GPIO_PIN_RESET);

  /*Configure GPIO pin : LCD_DISP_Pin */
  GPIO_InitStruct.Pin = LCD_DISP_Pin;
  GPIO_InitStruct.Mode = GPIO_MODE_OUTPUT_PP;
  GPIO_InitStruct.Pull = GPIO_NOPULL;
  GPIO_InitStruct.Speed = GPIO_SPEED_FREQ_LOW;
  HAL_GPIO_Init(LCD_DISP_GPIO_Port, &GPIO_InitStruct);

  /*Configure GPIO pin : USB_OTG_FS2_ID_Pin */
  GPIO_InitStruct.Pin = USB_OTG_FS2_ID_Pin;
  GPIO_InitStruct.Mode = GPIO_MODE_INPUT;
  GPIO_InitStruct.Pull = GPIO_NOPULL;
  HAL_GPIO_Init(USB_OTG_FS2_ID_GPIO_Port, &GPIO_InitStruct);

  /*Configure GPIO pin : B1_Pin */
  GPIO_InitStruct.Pin = B1_Pin;
  GPIO_InitStruct.Mode = GPIO_MODE_INPUT;
  GPIO_InitStruct.Pull = GPIO_NOPULL;
  HAL_GPIO_Init(B1_GPIO_Port, &GPIO_InitStruct);

  /*Configure GPIO pin : LD2_Pin */
  GPIO_InitStruct.Pin = LD2_Pin;
  GPIO_InitStruct.Mode = GPIO_MODE_OUTPUT_PP;
  GPIO_InitStruct.Pull = GPIO_NOPULL;
  GPIO_InitStruct.Speed = GPIO_SPEED_FREQ_LOW;
  HAL_GPIO_Init(LD2_GPIO_Port, &GPIO_InitStruct);

  /*Configure GPIO pin : LCD_INT_Pin */
  GPIO_InitStruct.Pin = LCD_INT_Pin;
  GPIO_InitStruct.Mode = GPIO_MODE_IT_RISING;
  GPIO_InitStruct.Pull = GPIO_NOPULL;
  HAL_GPIO_Init(LCD_INT_GPIO_Port, &GPIO_InitStruct);

  /*Configure GPIO pin : LCD_BL_Pin */
  GPIO_InitStruct.Pin = LCD_BL_Pin;
  GPIO_InitStruct.Mode = GPIO_MODE_INPUT;
  GPIO_InitStruct.Pull = GPIO_NOPULL;
  HAL_GPIO_Init(LCD_BL_GPIO_Port, &GPIO_InitStruct);

  /*Configure GPIO pin : USB_OTG_FS2_OverCurrent_Pin */
  GPIO_InitStruct.Pin = USB_OTG_FS2_OverCurrent_Pin;
  GPIO_InitStruct.Mode = GPIO_MODE_IT_RISING;
  GPIO_InitStruct.Pull = GPIO_NOPULL;
  HAL_GPIO_Init(USB_OTG_FS2_OverCurrent_GPIO_Port, &GPIO_InitStruct);

  /*Configure GPIO pin : LCD_RST_Pin */
  GPIO_InitStruct.Pin = LCD_RST_Pin;
  GPIO_InitStruct.Mode = GPIO_MODE_OUTPUT_PP;
  GPIO_InitStruct.Pull = GPIO_NOPULL;
  GPIO_InitStruct.Speed = GPIO_SPEED_FREQ_LOW;
  HAL_GPIO_Init(LCD_RST_GPIO_Port, &GPIO_InitStruct);

/* USER CODE BEGIN MX_GPIO_Init_2 */

  //turn on the display
  HAL_GPIO_WritePin( LCD_DISP_GPIO_Port, LCD_DISP_Pin, GPIO_PIN_SET );

/* USER CODE END MX_GPIO_Init_2 */
}

void StartDefaultTask(void *argument)
{
  /* init code for LWIP */
  MX_LWIP_Init();
  /* USER CODE BEGIN 5 */
  /* Infinite loop */

  uint32_t     i;

  bspInit();

  conReady = 1;

  screen.width    = 480;
  screen.height   = 272;
  screen.flags    = 0;
  screen.rowWidth = 480;
  screen.buffer   = osAlloc( screen.rowWidth * screen.height * 2, OS_ALLOC_MEMF_CHIP );

  gfDisplayBitmap( &screen );

  gfFillRect( &screen, 0, 0, screen.width - 1, screen.height - 1, gfColor( 0, 0, 0 ) );

  for( i = 0; i < 255; i++ )
  {
     gfCircle( &screen, screen.width / 2, screen.height / 2, i + 1, gfColor( ( 255 - i ), ( 255 - i ), ( 255 - i ) ) );
  }

  printf( "h745 gfxLib B20250124\r\n\r\n" );

  gfDrawTextOverlay( &screen, &con, 0, 0 );

  for(;;)
  {
     HAL_GPIO_WritePin(LD2_GPIO_Port, LD2_Pin, GPIO_PIN_RESET);

     osDelay( 500 );

     HAL_GPIO_WritePin(LD2_GPIO_Port, LD2_Pin, GPIO_PIN_SET);

     osDelay( 500 );

     printf( "*" );

     fflush( stdout );

     gfDrawTextOverlay( &screen, &con, 0, 0 );

     //     conRedraw( &con );
  }
  /* USER CODE END 5 */
}

void HAL_TIM_PeriodElapsedCallback(TIM_HandleTypeDef *htim)
{
  if (htim->Instance == TIM2) {
    HAL_IncTick();
  }
}

void Error_Handler(void)
{
  __disable_irq();
  while (1)
  {
  }
}
